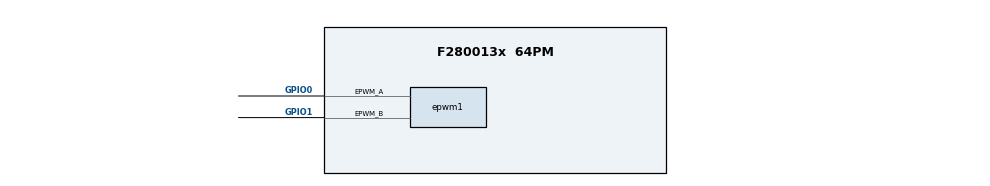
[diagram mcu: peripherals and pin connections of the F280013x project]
/**
 * @cliArgs --device "F280013x" --part "F280013x_64PM" --package "64PM" --context "system" --product "C2000WARE@6.00.00.00"
 * @versions {"tool":"1.24.0+4110"}
 */

/**
 * Import the modules used in this configuration.
 */
const adc     = scripting.addModule("/driverlib/adc.js", {}, false);
const adc1    = adc.addInstance();
const aio     = scripting.addModule("/driverlib/aio.js", {}, false);
const aio1    = aio.addInstance();
const analog  = scripting.addModule("/driverlib/analog.js", {}, false);
const analog1 = analog.addInstance();
const epwm    = scripting.addModule("/driverlib/epwm.js", {}, false);
const epwm1   = epwm.addInstance();
const epwm2   = epwm.addInstance();
const epwm3   = epwm.addInstance();
const gpio    = scripting.addModule("/driverlib/gpio.js", {}, false);
const gpio1   = gpio.addInstance();

/**
 * Write custom configuration values to the imported modules.
 */
adc1.$name                   = "myADC0";
adc1.enabledSOCs             = ["ADC_SOC_NUMBER0"];
adc1.adcClockPrescaler       = "ADC_CLK_DIV_3_0";
adc1.soc0SampleWindow        = 9;
adc1.interruptPulseMode      = "ADC_PULSE_END_OF_CONV";
adc1.enabledInts             = ["ADC_INT_NUMBER1"];
adc1.enableInterrupt1        = true;
adc1.registerInterrupts      = ["1"];
adc1.soc0Trigger             = "ADC_TRIGGER_EPWM3_SOCA";
adc1.socHighPriorityMode     = "ADC_PRI_SOC0_HIPRI";
adc1.adcInt1.enableInterrupt = true;

aio1.$name = "myAIO0";

analog1.$name            = "myANALOGPinMux0";
adc1.analog              = analog1;
analog1.useCase          = "CUSTOM";
analog1.useInterfacePins = ["A0/C15/CMP1_DACL"];
analog1.analog.$assign   = "ANALOG";

epwm1.$name                                                      = "myEPWM0";
epwm1.epwmTimebase_counterMode                                   = "EPWM_COUNTER_MODE_UP_DOWN";
epwm1.epwmActionQualifier_EPWM_AQ_OUTPUT_A_ON_TIMEBASE_UP_CMPA   = "EPWM_AQ_OUTPUT_HIGH";
epwm1.epwmActionQualifier_EPWM_AQ_OUTPUT_A_ON_TIMEBASE_DOWN_CMPA = "EPWM_AQ_OUTPUT_LOW";
epwm1.epwmActionQualifier_EPWM_AQ_OUTPUT_B_ON_TIMEBASE_ZERO      = "EPWM_AQ_OUTPUT_LOW";
epwm1.epwmActionQualifier_EPWM_AQ_OUTPUT_B_ON_TIMEBASE_UP_CMPB   = "EPWM_AQ_OUTPUT_HIGH";
epwm1.epwmActionQualifier_EPWM_AQ_OUTPUT_B_ON_TIMEBASE_DOWN_CMPB = "EPWM_AQ_OUTPUT_LOW";
epwm1.epwmEventTrigger_EPWM_SOC_A_triggerEnable                  = true;
epwm1.epwmEventTrigger_EPWM_SOC_A_triggerEventPrescalar          = "1";
epwm1.epwmEventTrigger_EPWM_SOC_A_triggerSource                  = "EPWM_SOC_TBCTR_ZERO";
epwm1.epwmDeadband_polarityFED                                   = "EPWM_DB_POLARITY_ACTIVE_LOW";
epwm1.epwmDeadband_enableRED                                     = true;
epwm1.epwmDeadband_enableFED                                     = true;
epwm1.epwmCounterCompare_cmpA                                    = 375;
epwm1.epwmTimebase_period                                        = 2999;
epwm1.epwmDeadband_delayRED                                      = 60;
epwm1.epwmDeadband_delayFED                                      = 60;
epwm1.epwm.$assign                                               = "EPWM3";
epwm1.epwm.epwm_aPin.$assign                                     = "GPIO0";
epwm1.epwm.epwm_bPin.$assign                                     = "GPIO1";

epwm2.$name = "myEPWM1";

epwm3.$name = "myEPWM2";

gpio1.$name     = "myGPIO0";
gpio1.direction = "GPIO_DIR_MODE_OUT";

/**
 * Pinmux solution for unlocked pins/peripherals. This ensures that minor changes to the automatic solver in a future
 * version of the tool will not impact the pinmux you originally saw.  These lines can be completely deleted in order to
 * re-solve from scratch.
 */
aio1.aioPin.$suggestSolution                           = "AIO233";
aio1.aioPin["AIO#"].$suggestSolution                   = "A15/C7";
analog1.analog["a0/c15/cmp1_daclPin"].$suggestSolution = "A0/C15/CMP1_DACL";
epwm2.epwm.$suggestSolution                            = "EPWM2";
epwm2.epwm.epwm_aPin.$suggestSolution                  = "A10/C10, GPIO230";
epwm2.epwm.epwm_bPin.$suggestSolution                  = "A6, GPIO228";
epwm3.epwm.$suggestSolution                            = "EPWM1";
epwm3.epwm.epwm_aPin.$suggestSolution                  = "A2/C9, GPIO224";
epwm3.epwm.epwm_bPin.$suggestSolution                  = "C6, GPIO226";
gpio1.gpioPin.$suggestSolution                         = "GPIO29";
